# ATmega1284P register map
Vendor: Atmel; File version: 1.0
CPU: other r0p0, little endian, no MPU, no FPU, 4 interrupt priority bits
Registers are 8-bit, read-write, reset 0x0 unless marked. A register's access mark holds for its fields unless they carry their own. Offsets are from the block's base; [hi:lo] are bit positions.

## TC3 — Timer/Counter, 16-bit
Base 0x00000038
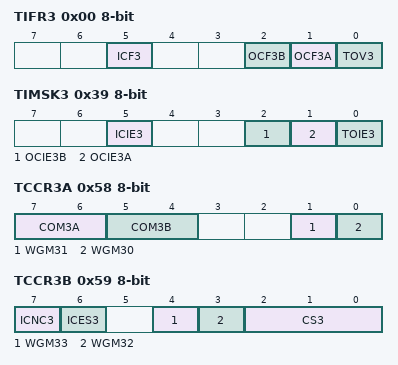
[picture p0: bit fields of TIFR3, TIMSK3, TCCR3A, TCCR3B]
0x00 TIFR3 — Timer/Counter Interrupt Flag register
  [5] ICF3 — Timer/Counter3 Input Capture Flag
  [2] OCF3B — Timer/Counter3 Output Compare B Match Flag
  [1] OCF3A — Timer/Counter3 Output Compare A Match Flag
  [0] TOV3 — Timer/Counter3 Overflow Flag
0x39 TIMSK3 — Timer/Counter3 Interrupt Mask Register
  [5] ICIE3 — Timer/Counter3 Input Capture Interrupt Enable
  [2] OCIE3B — Timer/Counter3 Output Compare B Match Interrupt Enable
  [1] OCIE3A — Timer/Counter3 Output Compare A Match Interrupt Enable
  [0] TOIE3 — Timer/Counter3 Overflow Interrupt Enable
0x58 TCCR3A — Timer/Counter3 Control Register A
  [7:6] COM3A — Compare Output Mode 3A, bits
  [5:4] COM3B — Compare Output Mode 3B, bits
  [1] WGM31 — Waveform Generation Mode
  [0] WGM30 — Waveform Generation Mode
0x59 TCCR3B — Timer/Counter3 Control Register B
  [7] ICNC3 — Input Capture 3 Noise Canceler
  [6] ICES3 — Input Capture 3 Edge Select
  [4] WGM33 — Waveform Generation Mode
  [3] WGM32 — Waveform Generation Mode
  [2:0] CS3 — Clock Select3 bits
    0=No Clock Source (Stopped); 1=Running, No Prescaling; 2=Running, CLK/8; 3=Running, CLK/64; 4=Running, CLK/256; 5=Running, CLK/1024; 6=Running, ExtClk Tx Falling Edge; 7=Running, ExtClk Tx Rising Edge
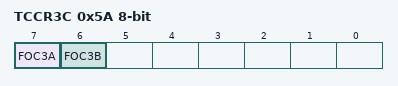
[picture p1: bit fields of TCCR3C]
0x5A TCCR3C — Timer/Counter3 Control Register C
  [7] FOC3A — Force Output Compare for Channel A
  [6] FOC3B — Force Output Compare for Channel B
0x5C TCNT3 16-bit (reset mask 0xFF) — Timer/Counter3 Bytes
  [15:0] TCNT3 — Timer/Counter3 bits
0x5E ICR3 16-bit (reset mask 0xFF) — Timer/Counter3 Input Capture Register Bytes
  [15:0] ICR3 — Timer/Counter3 Input Capture bits
0x60 OCR3A 16-bit (reset mask 0xFF) — Timer/Counter3 Output Compare Register A Bytes
  [15:0] OCR3A — Timer/Counter3 Output Compare A bits
0x62 OCR3B 16-bit (reset mask 0xFF) — Timer/Counter3 Output Compare Register B Bytes
  [15:0] OCR3B — Timer/Counter3 Output Compare B bits

## TWI — Two Wire Serial Interface
Base 0x000000B8
0x00 TWBR — TWI Bit Rate register
  [7:0] TWBR — TWI Bit Rate bits
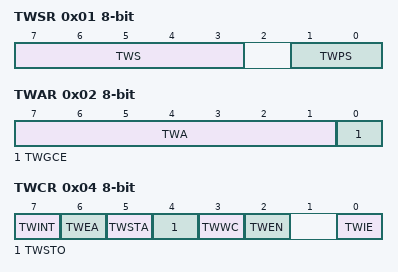
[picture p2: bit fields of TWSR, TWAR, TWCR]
0x01 TWSR — TWI Status Register
  [7:3] TWS — TWI Status
  [1:0] TWPS — TWI Prescaler
    0=1; 1=4; 2=16; 3=64
0x02 TWAR — TWI (Slave) Address register
  [7:1] TWA — TWI (Slave) Address register Bits
  [0] TWGCE — TWI General Call Recognition Enable Bit
0x03 TWDR — TWI Data register
  [7:0] TWD — TWI Data bits
0x04 TWCR — TWI Control Register
  [7] TWINT — TWI Interrupt Flag
  [6] TWEA — TWI Enable Acknowledge Bit
  [5] TWSTA — TWI Start Condition Bit
  [4] TWSTO — TWI Stop Condition Bit
  [3] TWWC — TWI Write Collition Flag
  [2] TWEN — TWI Enable Bit
  [0] TWIE — TWI Interrupt Enable
0x05 TWAMR — TWI (Slave) Address Mask Register
  [7:1] TWAM

## USART0 — USART
Base 0x000000C0
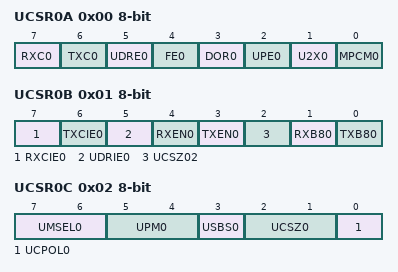
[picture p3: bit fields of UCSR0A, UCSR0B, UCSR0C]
0x00 UCSR0A — USART Control and Status Register A
  [7] RXC0 — USART Receive Complete
  [6] TXC0 — USART Transmitt Complete
  [5] UDRE0 — USART Data Register Empty
  [4] FE0 — Framing Error
  [3] DOR0 — Data overRun
  [2] UPE0 — Parity Error
  [1] U2X0 — Double the USART transmission speed
  [0] MPCM0 — Multi-processor Communication Mode
0x01 UCSR0B — USART Control and Status Register B
  [7] RXCIE0 — RX Complete Interrupt Enable
  [6] TXCIE0 — TX Complete Interrupt Enable
  [5] UDRIE0 — USART Data register Empty Interrupt Enable
  [4] RXEN0 — Receiver Enable
  [3] TXEN0 — Transmitter Enable
  [2] UCSZ02 — Character Size
  [1] RXB80 — Receive Data Bit 8
  [0] TXB80 — Transmit Data Bit 8
0x02 UCSR0C — USART Control and Status Register C
  [7:6] UMSEL0 — USART Mode Select
    0=Asynchronous USART; 1=Synchronous USART; 3=Master SPI
  [5:4] UPM0 — Parity Mode Bits
    0=Disabled; 2=Enabled, Even Parity; 3=Enabled, Odd Parity
  [3] USBS0 — Stop Bit Select
    0=1-bit; 1=2-bit
  [2:1] UCSZ0 — Character Size
  [0] UCPOL0 — Clock Polarity
0x04 UBRR0 16-bit (reset mask 0xFF) — USART Baud Rate Register Bytes
  [11:0] UBRR0 — USART Baud Rate Register
0x06 UDR0 — USART I/O Data Register
  [7:0] UDR0 — USART I/O Data bits

## USART1 — USART
Base 0x000000C8
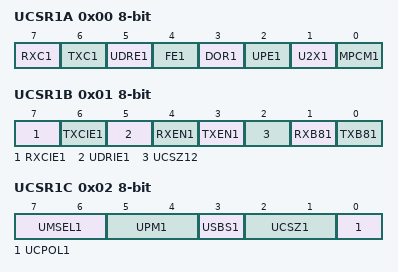
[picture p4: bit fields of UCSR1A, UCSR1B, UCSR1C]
0x00 UCSR1A — USART Control and Status Register A
  [7] RXC1 — USART Receive Complete
  [6] TXC1 — USART Transmitt Complete
  [5] UDRE1 — USART Data Register Empty
  [4] FE1 — Framing Error
  [3] DOR1 — Data overRun
  [2] UPE1 — Parity Error
  [1] U2X1 — Double the USART transmission speed
  [0] MPCM1 — Multi-processor Communication Mode
0x01 UCSR1B — USART Control and Status Register B
  [7] RXCIE1 — RX Complete Interrupt Enable
  [6] TXCIE1 — TX Complete Interrupt Enable
  [5] UDRIE1 — USART Data register Empty Interrupt Enable
  [4] RXEN1 — Receiver Enable
  [3] TXEN1 — Transmitter Enable
  [2] UCSZ12 — Character Size
  [1] RXB81 — Receive Data Bit 8
  [0] TXB81 — Transmit Data Bit 8
0x02 UCSR1C — USART Control and Status Register C
  [7:6] UMSEL1 — USART Mode Select
    0=Asynchronous USART; 1=Synchronous USART; 3=Master SPI
  [5:4] UPM1 — Parity Mode Bits
    0=Disabled; 2=Enabled, Even Parity; 3=Enabled, Odd Parity
  [3] USBS1 — Stop Bit Select
    0=1-bit; 1=2-bit
  [2:1] UCSZ1 — Character Size
  [0] UCPOL1 — Clock Polarity
0x04 UBRR1 16-bit (reset mask 0xFF) — USART Baud Rate Register Bytes
  [11:0] UBRR1 — USART Baud Rate Register
0x06 UDR1 — USART I/O Data Register
  [7:0] UDR1 — USART I/O Data bits

## WDT — Watchdog Timer
Base 0x00000060
0x00 WDTCSR — Watchdog Timer Control Register
  [7] WDIF — Watchdog Timeout Interrupt Flag
  [6] WDIE — Watchdog Timeout Interrupt Enable
  [4] WDCE — Watchdog Change Enable
  [3] WDE — Watch Dog Enable
  [5:0] WDP — Watchdog Timer Prescaler Bits
    0=Oscillator Cycles 2K; 1=Oscillator Cycles 4K; 2=Oscillator Cycles 8K; 3=Oscillator Cycles 16K; 4=Oscillator Cycles 32K; 5=Oscillator Cycles 64K; 6=Oscillator Cycles 128K; 7=Oscillator Cycles 256K
